# nrf5340_application register map
Vendor: Nordic Semiconductor; Series: nrf53; File version: 1
CPU: CM33 r0p4, little endian, MPU, FPU, 3 interrupt priority bits, 69 interrupts
Registers are 32-bit, read-write, reset 0x0 unless marked. A register's access mark holds for its fields unless they carry their own. Offsets are from the block's base; [hi:lo] are bit positions; {n}, {i} and the like mark numbered series; 'fields as' and 'values as' point back to an identical list.

## MUTEX_NS — MUTEX 0
Base 0x40030000
Same registers: MUTEX_S 0x50030000
{0x400+4i} MUTEX[{i}] (i=0..15) — Description collection: Mutex register
  [0] MUTEX — Mutex register n
    0=Unlocked (Mutex n is in unlocked state); 1=Locked (Mutex n is in locked state)

## USBREGULATOR_NS — USB Regulator 0
Base 0x40037000
Same registers: USBREGULATOR_S 0x50037000
0x100 EVENTS_USBDETECTED — Voltage supply detected on VBUS
  [0] EVENTS_USBDETECTED
    0=NotGenerated (Event not generated); 1=Generated (Event generated)
0x104 EVENTS_USBREMOVED — Voltage supply removed from VBUS
  [0] EVENTS_USBREMOVED
    values as EVENTS_USBDETECTED.EVENTS_USBDETECTED
0x108 EVENTS_USBPWRRDY — USB 3.3 V supply ready
  [0] EVENTS_USBPWRRDY
    values as EVENTS_USBDETECTED.EVENTS_USBDETECTED
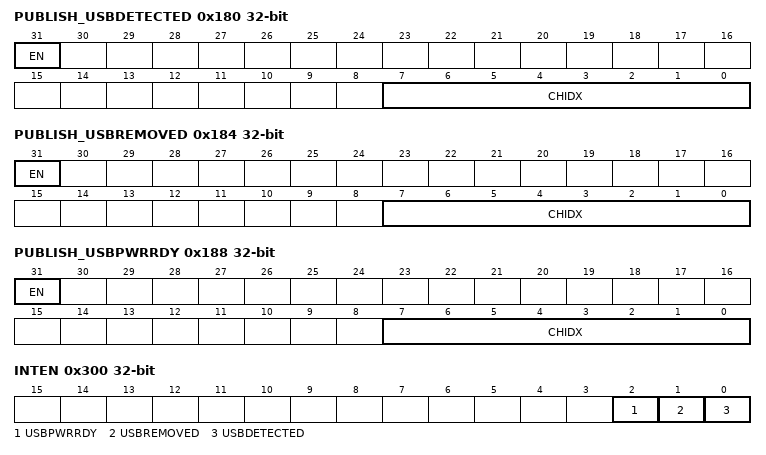
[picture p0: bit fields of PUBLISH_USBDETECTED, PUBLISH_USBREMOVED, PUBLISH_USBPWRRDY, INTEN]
0x180 PUBLISH_USBDETECTED — Publish configuration for event USBDETECTED
  [31] EN
    0=Disabled (Disable publishing); 1=Enabled (Enable publishing)
  [7:0] CHIDX — DPPI channel that event USBDETECTED will publish to.
0x184 PUBLISH_USBREMOVED — Publish configuration for event USBREMOVED
  [31] EN
    values as PUBLISH_USBDETECTED.EN
  [7:0] CHIDX — DPPI channel that event USBREMOVED will publish to.
0x188 PUBLISH_USBPWRRDY — Publish configuration for event USBPWRRDY
  [31] EN
    values as PUBLISH_USBDETECTED.EN
  [7:0] CHIDX — DPPI channel that event USBPWRRDY will publish to.
0x300 INTEN — Enable or disable interrupt
  [all] fields
    0=Disabled; 1=Enabled
  [2] USBPWRRDY — Enable or disable interrupt for event USBPWRRDY
  [1] USBREMOVED — Enable or disable interrupt for event USBREMOVED
  [0] USBDETECTED — Enable or disable interrupt for event USBDETECTED
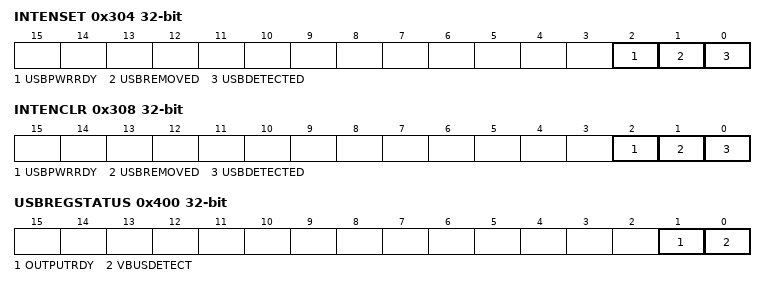
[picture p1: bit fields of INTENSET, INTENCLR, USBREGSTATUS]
0x304 INTENSET — Enable interrupt
  [all] fields
    on read: 0=Disabled (Read: Disabled); 1=Enabled (Read: Enabled) | on write: 1=Set (Enable)
  [2] USBPWRRDY — Write '1' to enable interrupt for event USBPWRRDY
  [1] USBREMOVED — Write '1' to enable interrupt for event USBREMOVED
  [0] USBDETECTED — Write '1' to enable interrupt for event USBDETECTED
0x308 INTENCLR — Disable interrupt
  [all] fields
    on read: 0=Disabled (Read: Disabled); 1=Enabled (Read: Enabled) | on write: 1=Clear (Disable)
  [2] USBPWRRDY — Write '1' to disable interrupt for event USBPWRRDY
  [1] USBREMOVED — Write '1' to disable interrupt for event USBREMOVED
  [0] USBDETECTED — Write '1' to disable interrupt for event USBDETECTED
0x400 USBREGSTATUS ro — USB supply status
  [1] OUTPUTRDY — USB supply output settling time elapsed
    0=NotReady (USBREG output settling time not elapsed); 1=Ready (USBREG output settling time elapsed (same information as USBPWRRDY event))
  [0] VBUSDETECT — VBUS input detection status (USBDETECTED and USBREMOVED events are derived from this information)
    0=NoVbus (VBUS voltage below valid threshold); 1=VbusPresent (VBUS voltage above valid threshold)

## KMU_NS — Key management unit 0
Base 0x40039000
Same registers: KMU_S 0x50039000
0x00 TASKS_PUSH_KEYSLOT wo — Push a key slot over secure APB
  [0] TASKS_PUSH_KEYSLOT
    1=Trigger task
0x100 EVENTS_KEYSLOT_PUSHED — Key slot successfully pushed over secure APB
  [0] EVENTS_KEYSLOT_PUSHED
    0=NotGenerated (Event not generated); 1=Generated (Event generated)
0x104 EVENTS_KEYSLOT_REVOKED — Key slot has been revoked and cannot be tasked for selection
  [0] EVENTS_KEYSLOT_REVOKED
    values as EVENTS_KEYSLOT_PUSHED.EVENTS_KEYSLOT_PUSHED
0x108 EVENTS_KEYSLOT_ERROR — No key slot selected, no destination address defined, or error during push operation
  [0] EVENTS_KEYSLOT_ERROR
    values as EVENTS_KEYSLOT_PUSHED.EVENTS_KEYSLOT_PUSHED
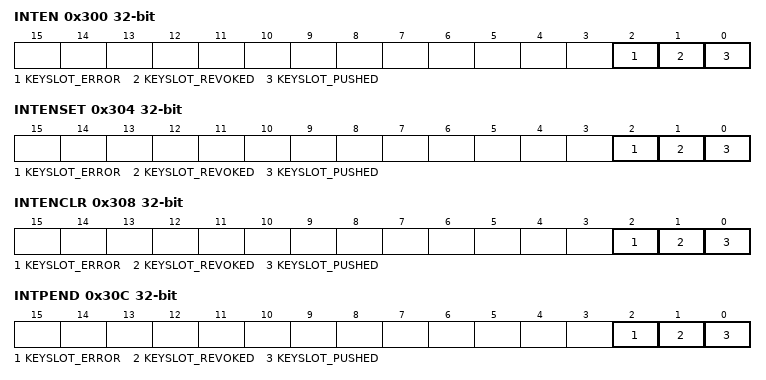
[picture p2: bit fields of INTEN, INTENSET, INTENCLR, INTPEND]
0x300 INTEN — Enable or disable interrupt
  [all] fields
    0=Disabled; 1=Enabled
  [2] KEYSLOT_ERROR — Enable or disable interrupt for event KEYSLOT_ERROR
  [1] KEYSLOT_REVOKED — Enable or disable interrupt for event KEYSLOT_REVOKED
  [0] KEYSLOT_PUSHED — Enable or disable interrupt for event KEYSLOT_PUSHED
0x304 INTENSET — Enable interrupt
  [all] fields
    on read: 0=Disabled (Read: Disabled); 1=Enabled (Read: Enabled) | on write: 1=Set (Enable)
  [2] KEYSLOT_ERROR — Write '1' to enable interrupt for event KEYSLOT_ERROR
  [1] KEYSLOT_REVOKED — Write '1' to enable interrupt for event KEYSLOT_REVOKED
  [0] KEYSLOT_PUSHED — Write '1' to enable interrupt for event KEYSLOT_PUSHED
0x308 INTENCLR — Disable interrupt
  [all] fields
    on read: 0=Disabled (Read: Disabled); 1=Enabled (Read: Enabled) | on write: 1=Clear (Disable)
  [2] KEYSLOT_ERROR — Write '1' to disable interrupt for event KEYSLOT_ERROR
  [1] KEYSLOT_REVOKED — Write '1' to disable interrupt for event KEYSLOT_REVOKED
  [0] KEYSLOT_PUSHED — Write '1' to disable interrupt for event KEYSLOT_PUSHED
0x30C INTPEND ro — Pending interrupts
  [all] fields
    on read: 0=NotPending (Read: Not pending); 1=Pending (Read: Pending)
  [2] KEYSLOT_ERROR — Read pending status of interrupt for event KEYSLOT_ERROR
  [1] KEYSLOT_REVOKED — Read pending status of interrupt for event KEYSLOT_REVOKED
  [0] KEYSLOT_PUSHED — Read pending status of interrupt for event KEYSLOT_PUSHED
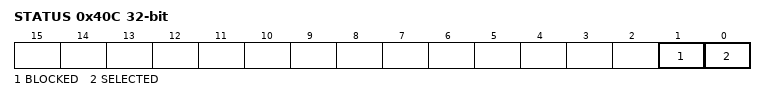
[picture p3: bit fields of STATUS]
0x40C STATUS ro — Status bits for KMU operation
  [1] BLOCKED — Violation status
    0=Disabled (No access violation detected); 1=Enabled (Access violation detected and blocked)
  [0] SELECTED — Key slot ID successfully selected by the KMU
    0=Disabled (No key slot ID selected by KMU); 1=Enabled (Key slot ID successfully selected by KMU)
0x500 SELECTKEYSLOT — Select key slot to be read over AHB or pushed over secure APB when TASKS_PUSH_KEYSLOT is started
  [7:0] ID — Select key slot ID to be read over AHB, or pushed over secure APB, when TASKS_PUSH_KEYSLOT is started. NOTE: ID=0 is not a valid key slot ID. The 0 ID should be used when the KMU is idle or not in use. NOTE: Index N in UICR->KEYSLOT.KEY[N] and UICR->KEYSLOT.CONFIG[N] corresponds to KMU key slot ID=N+1.
